# YC3122 register map
Series: ARMCM0; File version: 1.0
CPU: CM0 r1p0, little endian, no MPU, no FPU, 8 interrupt priority bits
Registers are 32-bit, read-write, reset 0x0 unless marked. A register's access mark holds for its fields unless they carry their own. Offsets are from the block's base; [hi:lo] are bit positions; {n}, {i} and the like mark numbered series.

## ADC_ANALOG — 32 ADC_ANALOG
Base 0x000FB240
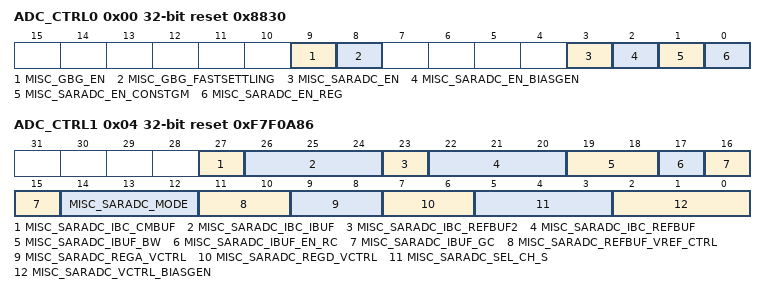
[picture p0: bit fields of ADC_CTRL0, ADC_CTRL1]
0x00 ADC_CTRL0 reset 0x8830
  [9] MISC_GBG_EN — The global bandgap enable
  [8] MISC_GBG_FASTSETTLING — The global bandgap fast settling enable
  [3] MISC_SARADC_EN — GPADC enable. 0: off; 1: on
  [2] MISC_SARADC_EN_BIASGEN — GPADC reference voltage enable. 0: off; 1: on
  [1] MISC_SARADC_EN_CONSTGM — GPADC constant Gm bias enable. 0: off; 1: on
  [0] MISC_SARADC_EN_REG — GPADC regulator enable. 0: off; 1: on
0x04 ADC_CTRL1 reset 0xF7F0A86
  [27] MISC_SARADC_IBC_CMBUF — GPADC biasgen buffer bias current control
  [26:24] MISC_SARADC_IBC_IBUF — GPAADC input buffer bias control
  [23] MISC_SARADC_IBC_REFBUF2 — GPADC bias voltage buffer bias current control
  [22:20] MISC_SARADC_IBC_REFBUF — GPADC differential reference voltage buffer bias current control
  [19:18] MISC_SARADC_IBUF_BW — GPADC input buffer bandwidth control
  [17] MISC_SARADC_IBUF_EN_RC — GPADC input buffer feedback capacitor enable
  [16:15] MISC_SARADC_IBUF_GC — GPADC full scale control
  [14:12] MISC_SARADC_MODE — 0=gpio,1=gpio diff,2=hvin,3=vinlpm,4=temperature
  [11:10] MISC_SARADC_REFBUF_VREF_CTRL — GPADC differential reference voltage control.
  [9:8] MISC_SARADC_REGA_VCTRL — GPADC analog regulator output voltage control. 0: 1.0V; 1: 1.1V; 2: 1.2V; 3: 1.3V
  [7:6] MISC_SARADC_REGD_VCTRL — GPADC digital regulator output voltage control. 0: 1.0V; 1: 1.1V; 2: 1.2V; 3: 1.3V
  [5:3] MISC_SARADC_SEL_CH_S — GPADC channel select
  [2:0] MISC_SARADC_VCTRL_BIASGEN — GPADC bias voltage control 425mV+25mV*misc_saradc_vctrl_biasgen

## ANA_RNG — 32 ANA_RNG
Base 0x000FB260
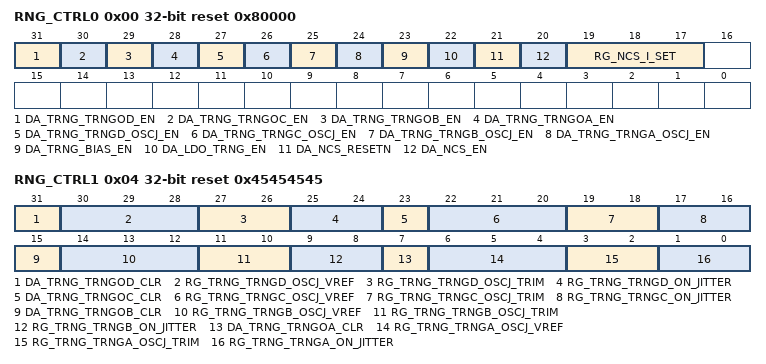
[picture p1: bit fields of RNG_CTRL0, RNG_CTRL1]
0x00 RNG_CTRL0 reset 0x80000 — RNG control
  [31] DA_TRNG_TRNGOD_EN — TRNGD HFOSC enable signal,high active
  [30] DA_TRNG_TRNGOC_EN — TRNGC HFOSC enable signal,high active
  [29] DA_TRNG_TRNGOB_EN — TRNGB HFOSC enable signal,high active
  [28] DA_TRNG_TRNGOA_EN — TRNGA HFOSC enable signal,high active
  [27] DA_TRNG_TRNGD_OSCJ_EN — TRNGD LFOSC enable signal,high active
  [26] DA_TRNG_TRNGC_OSCJ_EN — TRNGC LFOSC enable signal,high active
  [25] DA_TRNG_TRNGB_OSCJ_EN — TRNGB LFOSC enable signal,high active
  [24] DA_TRNG_TRNGA_OSCJ_EN — TRNGA LFOSC enable signal,high active
  [23] DA_TRNG_BIAS_EN — TRNG bias enable signal, high active
  [22] DA_LDO_TRNG_EN — Security TRNG LDO enable.
  [21] DA_NCS_RESETN — NCS reset
  [20] DA_NCS_EN — NCS enable
  [19:17] RG_NCS_I_SET — NCS current setting
0x04 RNG_CTRL1 reset 0x45454545 — RNG control
  [31] DA_TRNG_TRNGOD_CLR — TRNGD sample DFF output clear signal,low active
  [30:28] RG_TRNG_TRNGD_OSCJ_VREF — TRNGD LFOSC vref control signal
  [27:26] RG_TRNG_TRNGD_OSCJ_TRIM — TRNGD LFOSC frequency control signal
  [25:24] RG_TRNG_TRNGD_ON_JITTER — TRNGD LFOSC jitter control signal
  [23] DA_TRNG_TRNGOC_CLR — TRNGC sample DFF output clear signal,low active
  [22:20] RG_TRNG_TRNGC_OSCJ_VREF — TRNGC LFOSC vref control signal
  [19:18] RG_TRNG_TRNGC_OSCJ_TRIM — TRNGC LFOSC frequency control signal
  [17:16] RG_TRNG_TRNGC_ON_JITTER — TRNGC LFOSC jitter control signal
  [15] DA_TRNG_TRNGOB_CLR — TRNGB sample DFF output clear signal,low active
  [14:12] RG_TRNG_TRNGB_OSCJ_VREF — TRNGB LFOSC vref control signal
  [11:10] RG_TRNG_TRNGB_OSCJ_TRIM — TRNGB LFOSC frequency control signal
  [9:8] RG_TRNG_TRNGB_ON_JITTER — TRNGB LFOSC jitter control signal
  [7] DA_TRNG_TRNGOA_CLR — TRNGA sample DFF output clear signal,low active
  [6:4] RG_TRNG_TRNGA_OSCJ_VREF — TRNGA LFOSC vref control signal
  [3:2] RG_TRNG_TRNGA_OSCJ_TRIM — TRNGA LFOSC frequency control signal
  [1:0] RG_TRNG_TRNGA_ON_JITTER — TRNGA LFOSC jitter control signal

## ANA_CHGR — 32 ANA
Base 0x000FB270
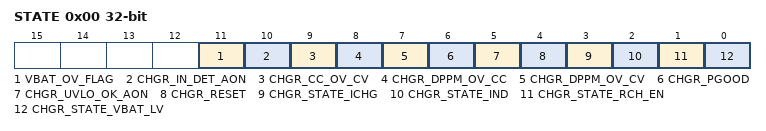
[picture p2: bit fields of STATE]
0x00 STATE — CHGR state
  [11] VBAT_OV_FLAG ro
  [10] CHGR_IN_DET_AON ro
  [9] CHGR_CC_OV_CV ro
  [8] CHGR_DPPM_OV_CC ro
  [7] CHGR_DPPM_OV_CV ro — CHGR_DPPM_OV_CC
  [6] CHGR_PGOOD ro
  [5] CHGR_UVLO_OK_AON ro
  [4] CHGR_RESET ro
  [3] CHGR_STATE_ICHG ro
  [2] CHGR_STATE_IND ro
  [1] CHGR_STATE_RCH_EN ro — CHGR_STAT_RCH_EN
  [0] CHGR_STATE_VBAT_LV ro

## USB — 32 USB
Base 0x000FB400
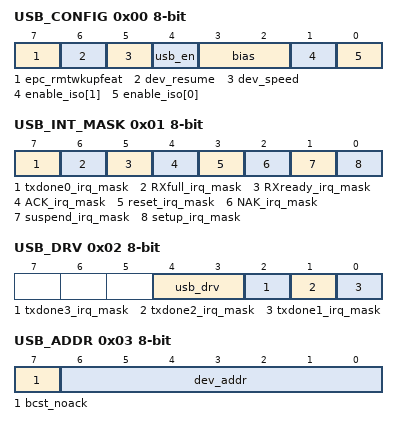
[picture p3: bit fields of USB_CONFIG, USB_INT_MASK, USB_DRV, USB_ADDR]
0x00 USB_CONFIG 8-bit
  [7] epc_rmtwkupfeat — endpoint wakeup enable
  [6] dev_resume — resume device
  [5] dev_speed — enable usb function
  [4] usb_en — enable usb function
  [3:2] bias — USB pad bias control
  [1] enable_iso[1] — 1:enable ISO for endpoint 2 IN
  [0] enable_iso[0] — enable ISO for endpoint 2 OUT
0x01 USB_INT_MASK 8-bit
  [7] txdone0_irq_mask — txdone0 interrupt mask
  [6] RXfull_irq_mask — RXfull interrupt mask
  [5] RXready_irq_mask — RXready interrupt mask
  [4] ACK_irq_mask — ACK interrupt mask
  [3] reset_irq_mask — reset interrupt mask
  [2] NAK_irq_mask — NAK interrupt mask
  [1] suspend_irq_mask — suspend interrupt mask
  [0] setup_irq_mask — setup interrupt mask
0x02 USB_DRV 8-bit
  [4:3] usb_drv
  [2] txdone3_irq_mask — txdone3 interrupt mask
  [1] txdone2_irq_mask — txdone2 interrupt mask
  [0] txdone1_irq_mask — txdone1 interrupt mask
0x03 USB_ADDR 8-bit
  [7] bcst_noack — disable broadcast(address 0) packet receive
  [6:0] dev_addr — device address
0x04 USB_RX_SADDR 24-bit
  [23:0] rx_startaddr — rx_start address
0x07 USB_RX_BUFLEN 24-bit
  [23:0] rx_buflen
{0xA+3i} USB_TX_SADDR{i} 24-bit (i=0..3)
  [23:0] tx_saddr{i} — tx_saddress{i}
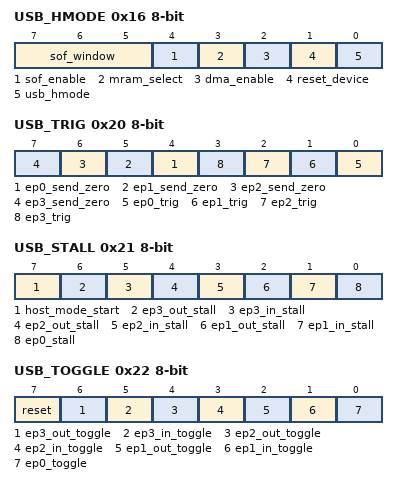
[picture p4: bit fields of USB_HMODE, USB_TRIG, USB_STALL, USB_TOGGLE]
0x16 USB_HMODE 8-bit
  [7:5] sof_window
  [4] sof_enable
  [3] mram_select
  [2] dma_enable — usb dma enable
  [1] reset_device — usb reset device
  [0] usb_hmode — usb host mode
0x1C USB_RX_RPTR
  [23:0] usb_rx_rptr — USB RX DMA read pointer
0x20 USB_TRIG 8-bit
  [n+4] ep{n}_send_zero wo (n=0..3) — endpoint {n} reply zero length packet to host
  [n] ep{n}_trig wo (n=0..3) — send endpoint {n} data in fifo
0x21 USB_STALL 8-bit
  [7] host_mode_start wo
  [6] ep3_out_stall wo — set endpoint 3 out to stall
  [5] ep3_in_stall wo — set endpoint 3 in to stall
  [4] ep2_out_stall wo — set endpoint 2 out to stall
  [3] ep2_in_stall wo — set endpoint 2 in to stall
  [2] ep1_out_stall wo — set endpoint 1 out to stall
  [1] ep1_in_stall wo — set endpoint 1 in to stall
  [0] ep0_stall wo — set endpoint 0 to stall
0x22 USB_TOGGLE 8-bit
  [7] reset wo — reset udc and pll and rxcnt
  [6] ep3_out_toggle wo — endpoint 3 out to data0
  [5] ep3_in_toggle wo — endpoint 3 in to data0
  [4] ep2_out_toggle wo — endpoint 2 out to data0
  [3] ep2_in_toggle wo — endpoint 2 in to data0
  [2] ep1_out_toggle wo — endpoint 1 out to data0
  [1] ep1_in_toggle wo — endpoint 1 in to data0
  [0] ep0_toggle wo — endpoint 0 to data0
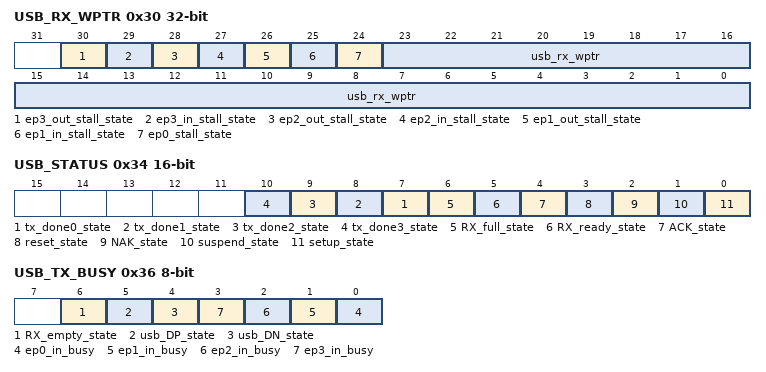
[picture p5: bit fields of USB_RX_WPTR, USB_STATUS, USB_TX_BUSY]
0x30 USB_RX_WPTR
  [30] ep3_out_stall_state — endpoint 3 out stall state
  [29] ep3_in_stall_state — endpoint 3 in stall state
  [28] ep2_out_stall_state — endpoint 2 out stall state
  [27] ep2_in_stall_state — endpoint 2 in stall state
  [26] ep1_out_stall_state — endpoint 1 out stall state
  [25] ep1_in_stall_state — endpoint 1 in stall state
  [24] ep0_stall_state — endpoint 0 stall state
  [23:0] usb_rx_wptr ro — USB RX DMA write pointer
0x34 USB_STATUS 16-bit
  [n+7] tx_done{n}_state (n=0..3) — usb tx done{n} state
  [6] RX_full_state — usb RX full state
  [5] RX_ready_state — usb RX ready state
  [4] ACK_state — usb ACK state
  [3] reset_state — usb reset state
  [2] NAK_state — usb NAK state
  [1] suspend_state — usb suspend state
  [0] setup_state — usb setup state
0x36 USB_TX_BUSY 8-bit
  [6] RX_empty_state ro — usb RX empty state
  [5] usb_DP_state ro
  [4] usb_DN_state ro
  [n] ep{n}_in_busy ro (n=0..3) — endpoint {n} in fifo busy state
0x37 USB_RXCNT 8-bit
  [7:0] usb_rxcnt ro — usb rx count
0x38 USB_SOF 16-bit
  [15:0] usb_sof_cnt ro — usb sof count
